# R7FA2E1A9 register map
Vendor: Renesas Electronics Corporation; Series: RA2; File version: 1.51.00
CPU: CM23 r1p0, little endian, MPU, no FPU, VTOR, 2 interrupt priority bits, 32 interrupts
Registers are 8-bit, read-write, reset 0x0 unless marked. A register's access mark holds for its fields unless they carry their own. Offsets are from the block's base; [hi:lo] are bit positions; {n}, {i} and the like mark numbered series; 'fields as' and 'values as' point back to an identical list; <NAME> marks a mode.

## CTSU — Capacitive Touch Sensing Unit
Base 0x40082000
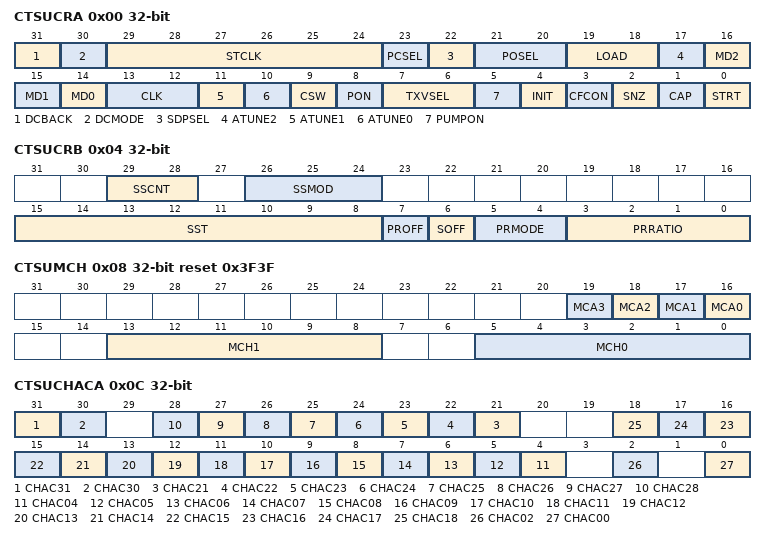
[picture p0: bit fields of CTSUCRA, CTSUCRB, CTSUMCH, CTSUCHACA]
0x00 CTSUCRA 32-bit — CTSU Control Register A
  [31] DCBACK — CTSU Current Measurement Feedback Select
    0=TSCAP pin is selected; 1=Measurement pin is selected. It is recommended in the current measurement mode.
  [30] DCMODE — CTSU Current Measurement Mode Select
    0=Electrostatic capacitance measurement mode; 1=Current measurement mode
  [29:24] STCLK — CTSU STCLK Select
  [23] PCSEL — CTSU Boost Circuit Clock Select
    0=Sensor drive pulse divided by 2; 1=STCLK
  [22] SDPSEL — CTSU Sensor Drive Pulse Select
    0=Random pulse; 1=Normal pulse using the sensor unit clock
  [21:20] POSEL — CTSU Non-Measured Channel Output Select
    0=Output low; 1=Hi-Z; 2=Setting prohibited; 3=Output a pulse in phase with the transmit channel
  [19:18] LOAD — CTSU Load Control During Measurement
    0=2.5 µA constant current load; 1=No load; 2=20 µA constant current load and overcurrent detector disabled; 3=Resistance load for calibration. To set LOAD[1:0] bits to resistance load for calibration, set these bits to 10b before they are set to 11b.
  [17] ATUNE2 — CTSU Current Range Adjustment
    0=80 µA when ATUNE1 = 0 40 µA when ATUNE1 = 1; 1=20 µA when ATUNE1 = 0 160 µA when ATUNE1 = 1
  [16] MD2 — CTSU Measurement Mode Select 2
    0=Measure the switched capacitor current and the DC current; 1=Measure the charge transfer by CFC circuit (parallel measurement)
  [15] MD1 — CTSU Measurement Mode Select 1
    0=One-time measurement (self-capacitance method); 1=Two times measurement (mutual capacitance method)
  [14] MD0 — CTSU Measurement Mode Select 0
    0=Single scan mode; 1=Multi-scan mode
  [13:12] CLK — CTSU Operating Clock Select
    0=PCLKB; 1=PCLKB/2 (PCLKB divided by 2); 2=PCLKB/4 (PCLKB divided by 4); 3=PCLKB/8 (PCLKB divided by 8)
  [11] ATUNE1 — CTSU Current Range Adjustment
    0=80 µA when ATUNE2 = 0 20 µA when ATUNE2 = 1; 1=40 µA when ATUNE2 = 0 160 µA when ATUNE2 = 1
  [10] ATUNE0 — CTSU Power Supply Operating Mode Setting
    0=VCC ≥ 2.4 V: Normal voltage operating mode VCC < 2.4 V: Setting prohibited; 1=Low-voltage operating mode
  [9] CSW — TSCAP Pin Enable
    0=Disable; 1=Enable
  [8] PON — CTSU Power On Control
    0=Power off the CTSU; 1=Power on the CTSU
  [7:6] TXVSEL — CTSU Transmission Power Supply Selection
    0=Selecting VCC as the power supply for the transmit pins of mutual capacitance method; 1=Selecting VCC as the power supply for the transmit pins of the mutual capacitance method. In addition, noise is reduced during GPIO operation. (Recommended); 2=Select VCC as the power source for the transmitter pins used as the active shield; 3=Setting prohibited
  [5] PUMPON — CTSU Boost Circuit Control
    0=Boost circuit off; 1=Boost circuit on
  [4] INIT wo — CTSU Control Block Initialization
  [3] CFCON — CTSU CFC Power On Control
    0=CFC power off; 1=CFC power on
  [2] SNZ — CTSU Wait State Power-Saving Enable
    0=Disable power-saving function during wait state; 1=Enable power-saving function during wait state
  [1] CAP — CTSU Measurement Operation Start Trigger Select
    0=Software trigger; 1=External trigger
  [0] STRT — CTSU Measurement Operation Start
    0=Stop measurement operation; 1=Start measurement operation
0x00 CTSUCRAL 16-bit (alternate view of CTSUCRA) — CTSU Control Register A
0x00 CTSUCR0 (alternate view of CTSUCRA) — CTSU Control Register A
0x01 CTSUCR1 (alternate view of CTSUCRA) — CTSU Control Register A
0x02 CTSUCRAH 16-bit (alternate view of CTSUCRA) — CTSU Control Register A
0x02 CTSUCR2 (alternate view of CTSUCRAH) — CTSU Control Register A
0x03 CTSUCR3 (alternate view of CTSUCRA) — CTSU Control Register A
0x04 CTSUCRB 32-bit — CTSU Control Register B
  [29:28] SSCNT — Adjusting the SUCLK frequency
    0=CTSUTRIMA.SUADJD + 0x00 (SDPSEL = 0) CTSUSUCLKx.SUADJDn + 0x00 (SDPSEL = 1); 1=CTSUTRIMA.SUADJD + 0x10 (SDPSEL = 0) CTSUSUCLKx.SUADJDn + 0x20 (SDPSEL = 1); 2=CTSUTRIMA.SUADJD + 0x20 (SDPSEL = 0) CTSUSUCLKx.SUADJDn + 0x40 (SDPSEL = 1); 3=CTSUTRIMA.SUADJD + 0x30 (SDPSEL = 0) CTSUSUCLKx.SUADJDn + 0x60 (SDPSEL = 1)
  [26:24] SSMOD — Spread Spectrum Modulation Frequency
    0=125 kHz (recommended); 1=83.3 kHz; 2=62.5 kHz; 3=31.3 kHz; other=Others (No spreading)
  [15:8] SST — Wait Time Sensor Stabilization
  [7] PROFF — Drive Pulse Phase Control
    0=The drive pulse phase is controlled by random numbers; 1=The drive pulse phase is not controlled by random numbers
  [6] SOFF — High-Pass Noise Reduction Function Disable
    0=Turn the spread spectrum on; 1=Turn the spread spectrum off
  [5:4] PRMODE — Phase Control Period
    0=510 pulses (512 pulses when PROFF = 1); 1=126 pulses (128 pulses when PROFF = 1); 2=62 pulses (64 pulses when PROFF = 1); 3=Setting prohibited
  [3:0] PRRATIO — Frequency of Drive Pulse Phase Control
0x04 CTSUCRBL 16-bit (alternate view of CTSUCRB) — CTSU Control Register B
0x04 CTSUSDPRS (alternate view of CTSUCRB) — CTSU Control Register B
0x05 CTSUSST (alternate view of CTSUCRB) — CTSU Control Register B
0x06 CTSUCRBH 16-bit (alternate view of CTSUCRB) — CTSU Control Register B
0x07 CTSUDCLKC (alternate view of CTSUCRB) — CTSU Control Register B
0x08 CTSUMCH 32-bit reset 0x3F3F — CTSU Measurement Channel Register
  [n+16] MCA{n} (n=0..3) — Multiple Clocks Control
    0=Disable; 1=Enable
  [13:8] MCH1 — CTSU Measurement Channel 1
    0=TS00; 2=TS02; {v}=TS{v:02} (v=4..18); {v}=TS{v} (v=21..28); {v}=TS{v} (v=30..34); 63=Measurement is being stopped
  [5:0] MCH0 — CTSU Measurement Channel 0
    values as MCH1
0x08 CTSUMCHL 16-bit (alternate view of CTSUMCH) — CTSU Measurement Channel Register
0x08 CTSUMCH0 (alternate view of CTSUMCH) — CTSU Measurement Channel Register
0x09 CTSUMCH1 (alternate view of CTSUMCH) — CTSU Measurement Channel Register
0x0A CTSUMCHH 16-bit reset 0x3F3F (alternate view of CTSUMCH) — CTSU Measurement Channel Register
0x0A CTSUMFAF reset 0x3F (alternate view of CTSUMCHH) — CTSU Measurement Channel Register
0x0C CTSUCHACA 32-bit — CTSU Channel Enable Control Register A
  [all] fields
    0=Do not measure; 1=Measure
  [31] CHAC31 — CTSU Channel Enable Control A
  [30] CHAC30 — CTSU Channel Enable Control A
  [n] CHAC{n} (n=21..28) — CTSU Channel Enable Control A
  [n] CHAC{n:02} (n=4..18) — CTSU Channel Enable Control A
  [2] CHAC02 — CTSU Channel Enable Control A
  [0] CHAC00 — CTSU Channel Enable Control A
0x0C CTSUCHACAL 16-bit (alternate view of CTSUCHACA) — CTSU Channel Enable Control Register A
0x0C CTSUCHAC0 (alternate view of CTSUCHACA) — CTSU Channel Enable Control Register A
0x0D CTSUCHAC1 (alternate view of CTSUCHACA) — CTSU Channel Enable Control Register A
0x0E CTSUCHACAH 16-bit (alternate view of CTSUCHACA) — CTSU Channel Enable Control Register A
0x0E CTSUCHAC2 (alternate view of CTSUCHACAH) — CTSU Channel Enable Control Register A
0x0F CTSUCHAC3 (alternate view of CTSUCHACA) — CTSU Channel Enable Control Register A
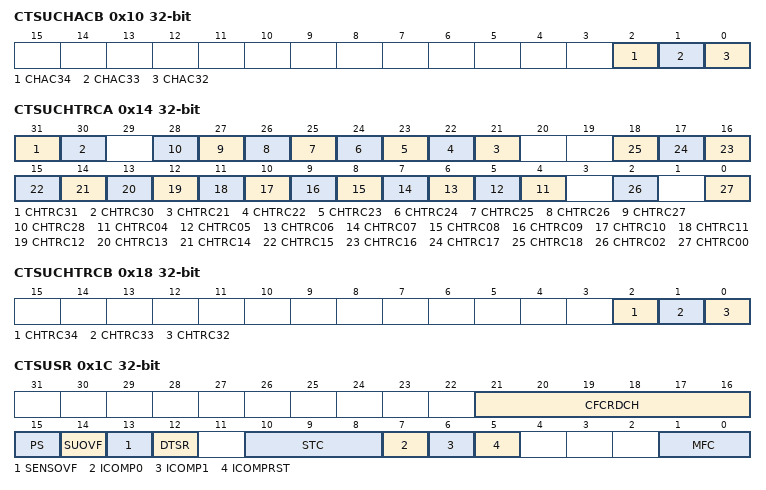
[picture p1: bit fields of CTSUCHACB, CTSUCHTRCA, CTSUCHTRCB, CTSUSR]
0x10 CTSUCHACB 32-bit — CTSU Channel Enable Control Register B
  [all] fields
    0=Do not measure; 1=Measure
  [2] CHAC34 — CTSU Channel Enable Control B
  [1] CHAC33 — CTSU Channel Enable Control B
  [0] CHAC32 — CTSU Channel Enable Control B
0x10 CTSUCHACBL 16-bit (alternate view of CTSUCHACB) — CTSU Channel Enable Control Register B
0x10 CTSUCHAC4 (alternate view of CTSUCHACB) — CTSU Channel Enable Control Register B
0x14 CTSUCHTRCA 32-bit — CTSU Channel Transmit/Receive Control Register A
  [all] fields
    0=Reception; 1=Transmission
  [31] CHTRC31 — CTSU Channel Transmit/Receive Control A
  [30] CHTRC30 — CTSU Channel Transmit/Receive Control A
  [n] CHTRC{n} (n=21..28) — CTSU Channel Transmit/Receive Control A
  [n] CHTRC{n:02} (n=4..18) — CTSU Channel Transmit/Receive Control A
  [2] CHTRC02 — CTSU Channel Transmit/Receive Control A
  [0] CHTRC00 — CTSU Channel Transmit/Receive Control A
0x14 CTSUCHTRCAL 16-bit (alternate view of CTSUCHTRCA) — CTSU Channel Transmit/Receive Control Register A
0x14 CTSUCHTRC0 (alternate view of CTSUCHTRCA) — CTSU Channel Transmit/Receive Control Register A
0x15 CTSUCHTRC1 (alternate view of CTSUCHTRCA) — CTSU Channel Transmit/Receive Control Register A
0x16 CTSUCHTRCAH 16-bit (alternate view of CTSUCHTRCA) — CTSU Channel Transmit/Receive Control Register A
0x16 CTSUCHTRC2 (alternate view of CTSUCHTRCAH) — CTSU Channel Transmit/Receive Control Register A
0x17 CTSUCHTRC3 (alternate view of CTSUCHTRCA) — CTSU Channel Transmit/Receive Control Register A
0x18 CTSUCHTRCB 32-bit — CTSU Channel Transmit/Receive Control Register B
  [all] fields
    0=Reception; 1=Transmission
  [2] CHTRC34 — CTSU Channel Transmit/Receive Control B
  [1] CHTRC33 — CTSU Channel Transmit/Receive Control B
  [0] CHTRC32 — CTSU Channel Transmit/Receive Control B
0x18 CTSUCHTRCBL 16-bit (alternate view of CTSUCHTRCB) — CTSU Channel Transmit/Receive Control Register B
0x18 CTSUCHTRC4 (alternate view of CTSUCHTRCB) — CTSU Channel Transmit/Receive Control Register B
0x1C CTSUSR 32-bit — CTSU Status Register
  [21:16] CFCRDCH — CTSU CFC Read Channel Select
    0=TS00; 2=TS02 (CFC); {v}=TS{v:02} (v=4..7); {v}=TS{v:02} (CFC) (v=8..16); 17=TS17; 18=TS18; {v}=TS{v} (v=21..25); 26=TS26 (CFC); 27=TS27 (CFC); 28=TS28 (CFC); {v}=TS{v} (CFC) (v=30..34)
  [15] PS ro — CTSU Mutual Capacitance Status Flag
    0=First measurement; 1=Second measurement
  [14] SUOVF — CTSU SUCLK Counter Overflow Flag
    0=No overflow occurred; 1=Overflow occurred
  [13] SENSOVF — CTSU Sensor Counter Overflow Flag
    0=No overflow occurred; 1=Overflow occurred
  [12] DTSR ro — CTSU Data Transfer Status Flag
    0=Read; 1=Not read
  [10:8] STC ro — CTSU Measurement Status Counter
    {v}=Status {v} (v=0..5)
  [7] ICOMP0 ro — TSCAP Voltage Error Monitor
    0=Normal TSCAP voltage; 1=Abnormal TSCAP voltage
  [6] ICOMP1 ro — CTSU Sense Current Error Monitor
    0=Normal sensor current; 1=Abnormal sensor current
  [5] ICOMPRST wo — CTSU CTSUICOMP1 Flag Reset
  [1:0] MFC — CTSU Multi-clock Counter
    {v}=Multi-clock {v} (v=0..3)
0x1C CTSUSRL 16-bit (alternate view of CTSUSR) — CTSU Status Register
0x1C CTSUSR0 (alternate view of CTSUSR) — CTSU Status Register
0x1D CTSUST (alternate view of CTSUSR) — CTSU Status Register
0x1E CTSUSRH 16-bit (alternate view of CTSUSR) — CTSU Status Register
0x1E CTSUSR2 (alternate view of CTSUSRH) — CTSU Status Register
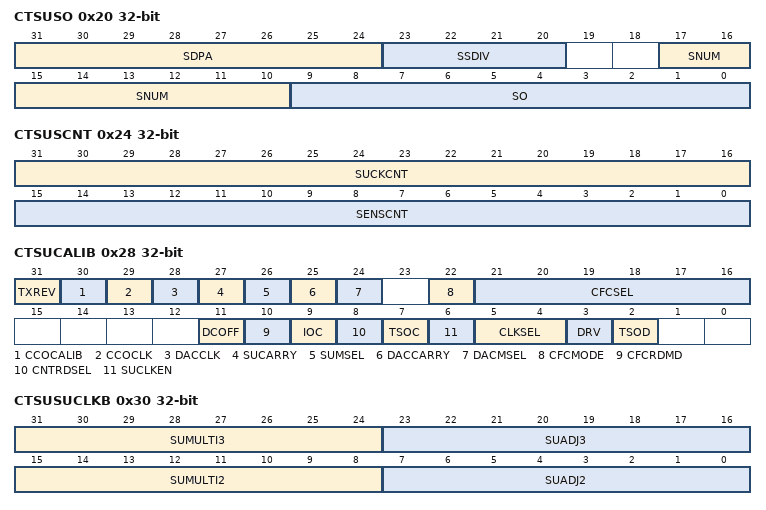
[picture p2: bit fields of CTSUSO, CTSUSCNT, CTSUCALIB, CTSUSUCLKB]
0x20 CTSUSO 32-bit — CTSU Sensor Offset Register
  [31:24] SDPA — CTSU Base Clock Setting
  [23:20] SSDIV — Spread Spectrum Frequency
  [17:10] SNUM — CTSU Measurement Count Setting
  [9:0] SO — CTSU Sensor Offset Adjustment
0x20 CTSUSO0 16-bit (alternate view of CTSUSO) — CTSU Sensor Offset Register
0x22 CTSUSO1 16-bit (alternate view of CTSUSO) — CTSU Sensor Offset Register
0x24 CTSUSCNT 32-bit ro — CTSU Sensor Counter Register
  [31:16] SUCKCNT — CTSU SUCLK Counter
  [15:0] SENSCNT — CTSU Sensor Counter
0x24 CTSUSC 16-bit ro (alternate view of CTSUSCNT) — CTSU Sensor Counter Register
0x28 CTSUCALIB 32-bit — CTSU Calibration Register
  [31] TXREV — Transmit Pin Inverted Output
    0=Normal; 1=Invert
  [30] CCOCALIB — Calibration Selection of Current Controlled Oscillator for Measurement
    0=Capacitance measurement mode; 1=Oscillator calibration mode
  [29] CCOCLK — Modulation Clock Select for Current Controlled Oscillator Input Current of SUCLK
    0=Operating clock selected by CTSUCRA.CLK [1:0]; 1=SUCLK
  [28] DACCLK — Modulation Clock Select for Offset Current Circuits
    0=Operating clock selected by CTSUCRA.CLK [1:0]; 1=SUCLK
  [27] SUCARRY — Current Control Oscillator Input Current Adjustment for SUCLK
    0=Normal operation; 1=All current sources can be turned on
  [26] SUMSEL — Current Control Oscillator Input Current Matrix Calibration Select
    0=Capacitance measurement mode; 1=Current control oscillator input current matrix calibration mode
  [25] DACCARRY — Offset Current Adjustment for Calibration
    0=Normal operation; 1=All current sources can be turned on
  [24] DACMSEL — Current Offset DAC Current Matrix Calibration Select
    0=Capacitance measurement mode; 1=Current offset DAC current Calibration mode
  [22] CFCMODE — CFC Oscillator Calibration Mode Select
    0=CFC current measurement (Capacitance measurement mode); 1=External current measurement for calibration
  [21:16] CFCSEL — Observation CFC Clock Select
  [11] DCOFF — Down Converter Control
    0=Voltage down converter operation (TSCAP voltage generation); 1=The voltage down converter is off
  [10] CFCRDMD — CFC Counter Read Mode Select
    0=Except for mutual capacitance parallel measurement mode; 1=Mutual capacitance parallel measurement mode
  [9] IOC — TS Pin Fixed Output Value Set
    0=Low level; 1=High level
  [8] CNTRDSEL — Read Count Select of Sensor Counter
    0=Read once; 1=Read twice
  [7] TSOC — Switched Capacitor Operation Calibration Select Bit
    0=Capacitance measurement mode; 1=Switched capacitor operation calibration mode
  [6] SUCLKEN — SUCLK Forced Oscillation Control
    0=SUCLK oscillation only during measurement; 1=SUCLK always oscillates
  [5:4] CLKSEL — Observation Clock Select
    0=Not selected (L fixed output); 1=Measurement clock (divided by 8); 2=CFC clock (divided by 8); 3=SUCLK (divided by 8)
  [3] DRV — Power Supply Calibration Select
    0=Capacitance measurement mode; 1=Power supply calibration mode
  [2] TSOD — TS Pin Fixed Output
    0=Capacitance measurement mode; 1=Output high or low from TS terminals (controlling by the IOC bit)
0x28 CTSUDBGR0 16-bit (alternate view of CTSUCALIB) — CTSU Calibration Register
0x2A CTSUDBGR1 16-bit (alternate view of CTSUCALIB) — CTSU Calibration Register
0x2C CTSUSUCLKA 32-bit — CTSU Sensor Unit Clock Control Register A
0x2C CTSUSUCLK0 16-bit (alternate view of CTSUSUCLKA) — CTSU Sensor Unit Clock Control Register A
0x2E CTSUSUCLK1 16-bit (alternate view of CTSUSUCLKA) — CTSU Sensor Unit Clock Control Register A
0x30 CTSUSUCLKB 32-bit — CTSU Sensor Unit Clock Control Register B
  [31:24] SUMULTI3 — CTSU SUCLK Multiplier Rate Setting
  [23:16] SUADJ3 — CTSU SUCLK Frequency Adjustment
  [15:8] SUMULTI2 — CTSU SUCLK Multiplier Rate Setting
  [7:0] SUADJ2 — CTSU SUCLK Frequency Adjustment
0x30 CTSUSUCLK2 16-bit (alternate view of CTSUSUCLKB) — CTSU Sensor Unit Clock Control Register B
0x32 CTSUSUCLK3 16-bit (alternate view of CTSUSUCLKB) — CTSU Sensor Unit Clock Control Register B
0x34 CTSUCFCCNT 32-bit ro — CTSU CFC Counter Register
  [15:0] CFCCNT — CTSU CFC Counter
0x34 CTSUCFCCNTL 16-bit ro (alternate view of CTSUCFCCNT) — CTSU CFC Counter Register
